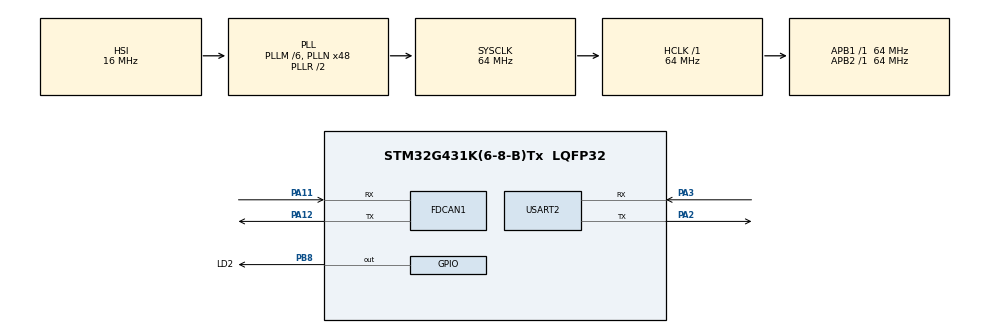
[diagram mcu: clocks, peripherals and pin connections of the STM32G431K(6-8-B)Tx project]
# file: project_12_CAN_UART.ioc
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FDCAN1.CalculateBaudRateNominal=500000
FDCAN1.CalculateTimeBitNominal=2000
FDCAN1.CalculateTimeQuantumNominal=125.0
FDCAN1.DataPrescaler=8
FDCAN1.DataSyncJumpWidth=3
FDCAN1.DataTimeSeg1=10
FDCAN1.DataTimeSeg2=3
FDCAN1.ExtFiltersNbr=1
FDCAN1.NominalPrescaler=8
FDCAN1.NominalSyncJumpWidth=3
FDCAN1.NominalTimeSeg1=13
FDCAN1.NominalTimeSeg2=2
FDCAN1.StdFiltersNbr=1
Mcu.Family=STM32G4
Mcu.Name=STM32G431K(6-8-B)Tx
Mcu.Package=LQFP32
NVIC.FDCAN1_IT0_IRQn=true\:2\:0\:true\:false\:true\:true\:true\:true
NVIC.PriorityGroup=NVIC_PRIORITYGROUP_4
NVIC.TIM2_IRQn=true\:4\:0\:true\:false\:true\:true\:true\:true
NVIC.TIM3_IRQn=true\:3\:0\:true\:false\:true\:true\:true\:true
NVIC.USART2_IRQn=true\:1\:0\:true\:false\:true\:true\:true\:true
PA11.Mode=FDCAN_Activate
PA11.Signal=FDCAN1_RX
PA12.Mode=FDCAN_Activate
PA12.Signal=FDCAN1_TX
PA2.Mode=Asynchronous
PA2.Signal=USART2_TX
PA3.Mode=Asynchronous
PA3.Signal=USART2_RX
PB8-BOOT0.GPIO_Label=LD2
PB8-BOOT0.Signal=GPIO_Output
PF0-OSC_IN.Mode=HSE-External-Oscillator
PF0-OSC_IN.Signal=RCC_OSC_IN
PF1-OSC_OUT.Mode=HSE-External-Oscillator
PF1-OSC_OUT.Signal=RCC_OSC_OUT
ProjectManager.HeapSize=0x200
ProjectManager.StackSize=0x400
ProjectManager.TargetToolchain=STM32CubeIDE
RCC.ADC12Freq_Value=64000000
RCC.AHBFreq_Value=64000000
RCC.APB1Freq_Value=64000000
RCC.APB1TimFreq_Value=64000000
RCC.APB2Freq_Value=64000000
RCC.APB2TimFreq_Value=64000000
RCC.CortexFreq_Value=64000000
RCC.EXTERNAL_CLOCK_VALUE=12288000
RCC.HCLKFreq_Value=64000000
RCC.HSE_VALUE=8000000
RCC.HSI48_VALUE=48000000
RCC.HSI_VALUE=16000000
RCC.LSE_VALUE=32768
RCC.PLLM=RCC_PLLM_DIV6
RCC.PLLN=48
RCC.SYSCLKFreq_VALUE=64000000
RCC.SYSCLKSource=RCC_SYSCLKSOURCE_PLLCLK
RCC.USBFreq_Value=64000000
RCC.VCOOutputFreq_Value=128000000
TIM2.PeriodNoDither=9
TIM2.Prescaler=63999
TIM2.TIM_MasterOutputTrigger=TIM_TRGO_UPDATE
TIM3.PeriodNoDither=99
TIM3.Prescaler=63999
TIM3.TIM_MasterOutputTrigger=TIM_TRGO_UPDATE
USART2.FIFOMode=FIFOMODE_DISABLE
USART2.OneBitSampling=UART_ONE_BIT_SAMPLE_DISABLE
USART2.OverSampling=UART_OVERSAMPLING_8
USART2.VirtualMode-Asynchronous=VM_ASYNC
VP_SYS_VS_DBSignals.Mode=DisableDeadBatterySignals
VP_TIM2_VS_ClockSourceINT.Mode=Internal
VP_TIM3_VS_ClockSourceINT.Mode=Internal
board=custom

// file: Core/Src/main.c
/* USER CODE BEGIN Header */
/**
  ******************************************************************************
  * @file           : main.c
  * @brief          : Main program body
  ******************************************************************************
  * @attention
  *
  * <h2><center>&copy; Copyright (c) 2020 STMicroelectronics.
  * All rights reserved.</center></h2>
  *
  * This software component is licensed by ST under BSD 3-Clause license,
  * the "License"; You may not use this file except in compliance with the
  * License. You may obtain a copy of the License at:
  *                        opensource.org/licenses/BSD-3-Clause
  *
  ******************************************************************************
  */
/* USER CODE END Header */
#include "main.h"

FDCAN_HandleTypeDef hfdcan1;

TIM_HandleTypeDef htim2;
TIM_HandleTypeDef htim3;

UART_HandleTypeDef huart2;

void SystemClock_Config(void);
static void MX_GPIO_Init(void);
static void MX_USART2_UART_Init(void);
static void MX_TIM3_Init(void);
static void MX_FDCAN1_Init(void);
static void MX_TIM2_Init(void);

int main(void)
{
  /* USER CODE BEGIN 1 */
  init_UART_values();
  init_CAN_values();
  /* USER CODE END 1 */

  /* MCU Configuration--------------------------------------------------------*/

  /* Reset of all peripherals, Initializes the Flash interface and the Systick. */
  HAL_Init();

  /* Configure the system clock */
  SystemClock_Config();

  /* Initialize all configured peripherals */
  MX_GPIO_Init();
  MX_USART2_UART_Init();
  MX_TIM3_Init();
  MX_FDCAN1_Init();
  MX_TIM2_Init();
  /* USER CODE BEGIN 2 */
  HAL_TIM_Base_Start_IT(&htim3);
  HAL_TIM_Base_Start_IT(&htim2);
  HAL_UART_Receive_IT(&huart2, (uint8_t *)UART_rx_buffer, UART_RX_MESSAGE_SIZE);
  init_CAN_filter();
  HAL_FDCAN_ConfigTimestampCounter(&hfdcan1, FDCAN_TIMESTAMP_PRESC_1);
  HAL_FDCAN_EnableTimestampCounter(&hfdcan1, FDCAN_TIMESTAMP_INTERNAL);
  HAL_FDCAN_Start(&hfdcan1);
  HAL_FDCAN_ActivateNotification(&hfdcan1, FDCAN_IT_RX_FIFO0_NEW_MESSAGE, FDCAN_TX_BUFFER0);

  /* USER CODE END 2 */

  /* Infinite loop */
  while (1)
  {

    /* USER CODE BEGIN 3 */
	//RX_queue_polling();
  }
  /* USER CODE END 3 */
}

void SystemClock_Config(void)
{
  RCC_OscInitTypeDef RCC_OscInitStruct = {0};
  RCC_ClkInitTypeDef RCC_ClkInitStruct = {0};

  /** Configure the main internal regulator output voltage
  */
  HAL_PWREx_ControlVoltageScaling(PWR_REGULATOR_VOLTAGE_SCALE1);

  /** Initializes the RCC Oscillators according to the specified parameters
  * in the RCC_OscInitTypeDef structure.
  */
  RCC_OscInitStruct.OscillatorType = RCC_OSCILLATORTYPE_HSI;
  RCC_OscInitStruct.HSIState = RCC_HSI_ON;
  RCC_OscInitStruct.HSICalibrationValue = RCC_HSICALIBRATION_DEFAULT;
  RCC_OscInitStruct.PLL.PLLState = RCC_PLL_ON;
  RCC_OscInitStruct.PLL.PLLSource = RCC_PLLSOURCE_HSI;
  RCC_OscInitStruct.PLL.PLLM = RCC_PLLM_DIV6;
  RCC_OscInitStruct.PLL.PLLN = 48;
  RCC_OscInitStruct.PLL.PLLP = RCC_PLLP_DIV2;
  RCC_OscInitStruct.PLL.PLLQ = RCC_PLLQ_DIV2;
  RCC_OscInitStruct.PLL.PLLR = RCC_PLLR_DIV2;
  if (HAL_RCC_OscConfig(&RCC_OscInitStruct) != HAL_OK)
  {
    Error_Handler();
  }

  /** Initializes the CPU, AHB and APB buses clocks
  */
  RCC_ClkInitStruct.ClockType = RCC_CLOCKTYPE_HCLK|RCC_CLOCKTYPE_SYSCLK
                              |RCC_CLOCKTYPE_PCLK1|RCC_CLOCKTYPE_PCLK2;
  RCC_ClkInitStruct.SYSCLKSource = RCC_SYSCLKSOURCE_PLLCLK;
  RCC_ClkInitStruct.AHBCLKDivider = RCC_SYSCLK_DIV1;
  RCC_ClkInitStruct.APB1CLKDivider = RCC_HCLK_DIV1;
  RCC_ClkInitStruct.APB2CLKDivider = RCC_HCLK_DIV1;

  if (HAL_RCC_ClockConfig(&RCC_ClkInitStruct, FLASH_LATENCY_2) != HAL_OK)
  {
    Error_Handler();
  }
}

static void MX_FDCAN1_Init(void)
{

  hfdcan1.Instance = FDCAN1;
  hfdcan1.Init.ClockDivider = FDCAN_CLOCK_DIV1;
  hfdcan1.Init.FrameFormat = FDCAN_FRAME_CLASSIC;
  hfdcan1.Init.Mode = FDCAN_MODE_NORMAL;
  hfdcan1.Init.AutoRetransmission = DISABLE;
  hfdcan1.Init.TransmitPause = DISABLE;
  hfdcan1.Init.ProtocolException = DISABLE;
  hfdcan1.Init.NominalPrescaler = 8;
  hfdcan1.Init.NominalSyncJumpWidth = 3;
  hfdcan1.Init.NominalTimeSeg1 = 13;
  hfdcan1.Init.NominalTimeSeg2 = 2;
  hfdcan1.Init.DataPrescaler = 8;
  hfdcan1.Init.DataSyncJumpWidth = 3;
  hfdcan1.Init.DataTimeSeg1 = 10;
  hfdcan1.Init.DataTimeSeg2 = 3;
  hfdcan1.Init.StdFiltersNbr = 1;
  hfdcan1.Init.ExtFiltersNbr = 1;
  hfdcan1.Init.TxFifoQueueMode = FDCAN_TX_FIFO_OPERATION;
  if (HAL_FDCAN_Init(&hfdcan1) != HAL_OK)
  {
    Error_Handler();
  }

}

static void MX_TIM2_Init(void)
{

  TIM_ClockConfigTypeDef sClockSourceConfig = {0};
  TIM_MasterConfigTypeDef sMasterConfig = {0};

  htim2.Instance = TIM2;
  htim2.Init.Prescaler = 63999;
  htim2.Init.CounterMode = TIM_COUNTERMODE_UP;
  htim2.Init.Period = 9;
  htim2.Init.ClockDivision = TIM_CLOCKDIVISION_DIV1;
  htim2.Init.AutoReloadPreload = TIM_AUTORELOAD_PRELOAD_DISABLE;
  if (HAL_TIM_Base_Init(&htim2) != HAL_OK)
  {
    Error_Handler();
  }
  sClockSourceConfig.ClockSource = TIM_CLOCKSOURCE_INTERNAL;
  if (HAL_TIM_ConfigClockSource(&htim2, &sClockSourceConfig) != HAL_OK)
  {
    Error_Handler();
  }
  sMasterConfig.MasterOutputTrigger = TIM_TRGO_UPDATE;
  sMasterConfig.MasterSlaveMode = TIM_MASTERSLAVEMODE_DISABLE;
  if (HAL_TIMEx_MasterConfigSynchronization(&htim2, &sMasterConfig) != HAL_OK)
  {
    Error_Handler();
  }

}

static void MX_TIM3_Init(void)
{

  TIM_ClockConfigTypeDef sClockSourceConfig = {0};
  TIM_MasterConfigTypeDef sMasterConfig = {0};

  htim3.Instance = TIM3;
  htim3.Init.Prescaler = 63999;
  htim3.Init.CounterMode = TIM_COUNTERMODE_UP;
  htim3.Init.Period = 99;
  htim3.Init.ClockDivision = TIM_CLOCKDIVISION_DIV1;
  htim3.Init.AutoReloadPreload = TIM_AUTORELOAD_PRELOAD_DISABLE;
  if (HAL_TIM_Base_Init(&htim3) != HAL_OK)
  {
    Error_Handler();
  }
  sClockSourceConfig.ClockSource = TIM_CLOCKSOURCE_INTERNAL;
  if (HAL_TIM_ConfigClockSource(&htim3, &sClockSourceConfig) != HAL_OK)
  {
    Error_Handler();
  }
  sMasterConfig.MasterOutputTrigger = TIM_TRGO_UPDATE;
  sMasterConfig.MasterSlaveMode = TIM_MASTERSLAVEMODE_DISABLE;
  if (HAL_TIMEx_MasterConfigSynchronization(&htim3, &sMasterConfig) != HAL_OK)
  {
    Error_Handler();
  }

}

static void MX_USART2_UART_Init(void)
{

  huart2.Instance = USART2;
  huart2.Init.BaudRate = 115200;
  huart2.Init.WordLength = UART_WORDLENGTH_8B;
  huart2.Init.StopBits = UART_STOPBITS_1;
  huart2.Init.Parity = UART_PARITY_NONE;
  huart2.Init.Mode = UART_MODE_TX_RX;
  huart2.Init.HwFlowCtl = UART_HWCONTROL_NONE;
  huart2.Init.OverSampling = UART_OVERSAMPLING_8;
  huart2.Init.OneBitSampling = UART_ONE_BIT_SAMPLE_DISABLE;
  huart2.Init.ClockPrescaler = UART_PRESCALER_DIV1;
  huart2.AdvancedInit.AdvFeatureInit = UART_ADVFEATURE_NO_INIT;
  if (HAL_UART_Init(&huart2) != HAL_OK)
  {
    Error_Handler();
  }
  if (HAL_UARTEx_SetTxFifoThreshold(&huart2, UART_TXFIFO_THRESHOLD_1_8) != HAL_OK)
  {
    Error_Handler();
  }
  if (HAL_UARTEx_SetRxFifoThreshold(&huart2, UART_RXFIFO_THRESHOLD_1_8) != HAL_OK)
  {
    Error_Handler();
  }
  if (HAL_UARTEx_DisableFifoMode(&huart2) != HAL_OK)
  {
    Error_Handler();
  }

}

static void MX_GPIO_Init(void)
{
  GPIO_InitTypeDef GPIO_InitStruct = {0};

  /* GPIO Ports Clock Enable */
  __HAL_RCC_GPIOF_CLK_ENABLE();
  __HAL_RCC_GPIOA_CLK_ENABLE();
  __HAL_RCC_GPIOB_CLK_ENABLE();

  /*Configure GPIO pin Output Level */
  HAL_GPIO_WritePin(LD2_GPIO_Port, LD2_Pin, GPIO_PIN_RESET);

  /*Configure GPIO pin : LD2_Pin */
  GPIO_InitStruct.Pin = LD2_Pin;
  GPIO_InitStruct.Mode = GPIO_MODE_OUTPUT_PP;
  GPIO_InitStruct.Pull = GPIO_NOPULL;
  GPIO_InitStruct.Speed = GPIO_SPEED_FREQ_LOW;
  HAL_GPIO_Init(LD2_GPIO_Port, &GPIO_InitStruct);

}

void Error_Handler(void)
{
}
